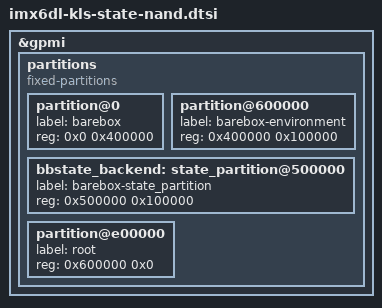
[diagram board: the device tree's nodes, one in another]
// SPDX-License-Identifier: (GPL-2.0-or-later OR MIT)
/*
 * Copyright (C) 2021 KLS Martin GmbH & Co KG,
 * Author: Leif Middelschulte <leif.middelschulte@klsmartin.com>
 */

&gpmi {
	/delete-node/ partitions;
	partitions {
		compatible = "fixed-partitions";
		#address-cells = <1>;
		#size-cells = <1>;

		partition@0 {
			label = "barebox";
			reg = <0x0 0x400000>;
		};

		partition@600000 {
			label = "barebox-environment";
			reg = <0x400000 0x100000>;
		};

		bbstate_backend: state_partition@500000 {
			label = "barebox-state_partition";
			reg = <0x500000 0x100000>;
		};

		partition@e00000 {
			label = "root";
			reg = <0x600000 0x0>;
		};
	};
};
